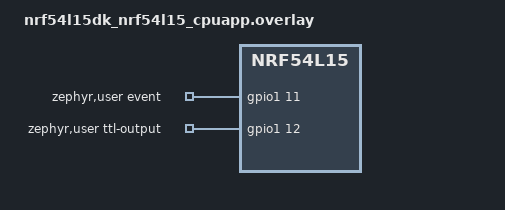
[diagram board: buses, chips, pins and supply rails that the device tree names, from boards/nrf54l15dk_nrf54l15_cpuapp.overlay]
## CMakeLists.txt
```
cmake_minimum_required(VERSION 3.20.0)
find_package(Zephyr REQUIRED HINTS $ENV{ZEPHYR_BASE})

project(galapagos)

target_include_directories(app PRIVATE
  ${CMAKE_CURRENT_SOURCE_DIR}/../shared/include
  ${CMAKE_CURRENT_SOURCE_DIR}/src
)

target_sources(app PRIVATE
  src/main.cpp
  src/debug_log.cpp
  src/record_stream.cpp
  src/hardware.cpp
  src/application.cpp
  src/ble_service.cpp
  ../shared/src/sdc_anchor_report.c
  ../shared/src/transport.cpp
  ../shared/src/fairy_protocol.cpp
  ../shared/src/adelie_protocol.cpp
  ../shared/src/magellan_protocol.cpp
)

target_compile_options(app PRIVATE
  -Wall
  -Wextra
  -Wshadow
  $<$<COMPILE_LANGUAGE:CXX>:-fno-exceptions>
  $<$<COMPILE_LANGUAGE:CXX>:-fno-rtti>
)

if(DEFINED FAIRY_ENABLE_DEBUG_STREAM)
  target_compile_definitions(app PRIVATE
    FAIRY_ENABLE_DEBUG_STREAM=${FAIRY_ENABLE_DEBUG_STREAM}
  )
endif()
```

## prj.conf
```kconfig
CONFIG_CPP=y
CONFIG_STD_CPP17=y
CONFIG_GLIBCXX_LIBCPP=y


CONFIG_SERIAL=y
CONFIG_CONSOLE=y
CONFIG_UART_CONSOLE=y
CONFIG_PRINTK=y
CONFIG_CBPRINTF_FULL_INTEGRAL=y

CONFIG_BT=y
CONFIG_BT_PERIPHERAL=y
CONFIG_BT_CENTRAL=n
CONFIG_BT_DEVICE_NAME="galapagos"
CONFIG_BT_MAX_CONN=1
CONFIG_BT_CTLR_SDC_PERIPHERAL_COUNT=1
CONFIG_BT_CTLR_SDC_CONN_ANCHOR_POINT_REPORT=y
CONFIG_BT_HCI_VS_EVT_USER=y

CONFIG_BT_L2CAP_TX_MTU=247
CONFIG_BT_BUF_ACL_RX_SIZE=251
CONFIG_BT_BUF_ACL_TX_SIZE=251
CONFIG_BT_BUF_ACL_TX_COUNT=12
CONFIG_BT_BUF_EVT_RX_COUNT=13
CONFIG_BT_CTLR_PHY_2M=y

CONFIG_MAIN_STACK_SIZE=4096
CONFIG_SYSTEM_WORKQUEUE_STACK_SIZE=4096
CONFIG_HEAP_MEM_POOL_SIZE=2048
CONFIG_ASSERT=y
CONFIG_LOG=n

CONFIG_GPIO=n
CONFIG_NRFX_GPIOTE=y
CONFIG_NRFX_GPPI=y
CONFIG_NRFX_GRTC=y

CONFIG_CLOCK_CONTROL=y
CONFIG_CLOCK_CONTROL_NRF=y
CONFIG_CLOCK_CONTROL_NRF_K32SRC_XTAL=y
```

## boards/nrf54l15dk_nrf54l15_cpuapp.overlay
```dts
#include <zephyr/dt-bindings/gpio/gpio.h>

/ {
    zephyr,user {
        event-gpios = <&gpio1 11 GPIO_ACTIVE_HIGH>;
        ttl-output-gpios = <&gpio1 12 GPIO_ACTIVE_HIGH>;
    };
};
```

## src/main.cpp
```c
#include <zephyr/kernel.h>

#include "application.hpp"
#include "ble_service.hpp"
#include "debug_log.hpp"
#include "hardware.hpp"
#include "record_stream.hpp"

int main() {
  galapagos_stream::initialize();
  int error = galapagos_hardware::initialize();
  if (error == 0) {
    galapagos_application::initialize();
    error = galapagos_ble::initialize();
  }
  if (error != 0) {
    galapagos_debug::log("FATAL galapagos status=%d\r\n", error);
  } else {
    galapagos_debug::log(
        "READY galapagos fairy=3 adelie=2 transport=1 timer_hz=16000000\r\n");
  }
  while (true) {
    k_sleep(K_SECONDS(60));
  }
  return 0;
}
```

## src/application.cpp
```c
#include "application.hpp"

#include <zephyr/kernel.h>
#include <zephyr/sys/atomic.h>

#include "fairy_shared/adelie_protocol.hpp"
#include "fairy_shared/fairy_protocol.hpp"
#include "fairy_shared/tlv.hpp"
#include "hardware.hpp"
#include "record_stream.hpp"

namespace galapagos_application {
namespace {

atomic_t active_session;
std::uint32_t last_command;
bool link_connected;
K_SEM_DEFINE(start_sem, 0, 1);

std::uint64_t extend_controller_anchor_us(std::uint64_t raw_anchor_us) {
  /*
   * The SoftDevice anchor report contains a wrapping 32-bit microsecond
   * timestamp. Extend it around the local 64-bit GRTC time before feeding the
   * clock model; otherwise every ~71.6 minutes the model jumps into the past
   * and scheduled TTL timestamps are rejected by the hardware.
   */
  constexpr std::uint64_t wrap = 1ULL << 32U;
  constexpr std::uint64_t half_wrap = wrap / 2ULL;
  const std::uint64_t near_us = galapagos_hardware::now_ticks() / 16ULL;
  std::uint64_t extended =
      (near_us & ~(wrap - 1ULL)) | (raw_anchor_us & (wrap - 1ULL));
  if (extended + half_wrap < near_us) {
    extended += wrap;
  } else if (extended > near_us + half_wrap && extended >= wrap) {
    extended -= wrap;
  }
  return extended;
}

std::uint32_t session_value() {
  return static_cast<std::uint32_t>(atomic_get(&active_session));
}

void publish_boot() {
  std::uint8_t payload[64]{};
  fairy::protocol::TlvWriter fields(payload, sizeof(payload));
  (void)fields.string(
      static_cast<std::uint16_t>(fairy::protocol::Field::board_kind),
      "nrf54l15dk");
  (void)fields.string(
      static_cast<std::uint16_t>(fairy::protocol::Field::firmware_version),
      "3.0.0");
  (void)galapagos_stream::publish_record(
      fairy::protocol::RecordType::boot, fairy::protocol::first_after_reset,
      galapagos_hardware::now_ticks(), 0, payload, fields.size());
}

bool command_u32(const fairy::protocol::AdelieMessageView &message,
                 fairy::protocol::CommandField wanted, std::uint32_t &value) {
  fairy::protocol::TlvReader reader(message.payload,
                                    message.header.payload_length);
  fairy::protocol::FieldView field;
  while (reader.next(field)) {
    if (field.tag == static_cast<std::uint16_t>(wanted)) {
      return fairy::protocol::TlvReader::as_u32(field, value);
    }
  }
  return false;
}

void publish_result(const fairy::protocol::AdelieMessageView &command,
                    fairy::protocol::Status status, std::uint64_t ticks) {
  std::uint8_t payload[64]{};
  fairy::protocol::TlvWriter fields(payload, sizeof(payload));
  (void)fields.u32(
      static_cast<std::uint16_t>(fairy::protocol::Field::command_id),
      command.header.command_id);
  (void)fields.u16(
      static_cast<std::uint16_t>(fairy::protocol::Field::operation),
      static_cast<std::uint16_t>(command.header.opcode));
  (void)fields.u8(static_cast<std::uint16_t>(fairy::protocol::Field::status),
                  static_cast<std::uint8_t>(status));
  (void)fields.u64(
      static_cast<std::uint16_t>(fairy::protocol::Field::requested_ticks),
      command.header.execute_at_ticks);
  (void)fields.u64(
      static_cast<std::uint16_t>(fairy::protocol::Field::actual_ticks), ticks);
  (void)galapagos_stream::publish_record(
      fairy::protocol::RecordType::command_result,
      fairy::protocol::critical | fairy::protocol::actual_time, ticks,
      session_value(), payload, fields.size());
}

void health_thread(void *, void *, void *) {
  k_sem_take(&start_sem, K_FOREVER);
  while (true) {
    k_sleep(K_SECONDS(1));
    const std::uint64_t ticks = galapagos_hardware::now_ticks();
    std::uint8_t payload[80]{};
    fairy::protocol::TlvWriter fields(payload, sizeof(payload));
    (void)fields.u32(
        static_cast<std::uint16_t>(fairy::protocol::Field::uptime_ms),
        static_cast<std::uint32_t>(ticks / 16'000ULL));
    (void)fields.u32(
        static_cast<std::uint16_t>(fairy::protocol::Field::dropped_records),
        galapagos_stream::dropped());
    (void)fields.u32(
        static_cast<std::uint16_t>(fairy::protocol::Field::transport_errors),
        galapagos_stream::transport_errors());
    (void)fields.boolean(
        static_cast<std::uint16_t>(fairy::protocol::Field::state),
        galapagos_hardware::ttl_armed());
    (void)galapagos_stream::publish_record(fairy::protocol::RecordType::health,
                                           0, ticks, session_value(), payload,
                                           fields.size());
  }
}

K_THREAD_DEFINE(health_thread_id, 1536, health_thread, nullptr, nullptr,
                nullptr, 9, 0, 0);

} // namespace

void initialize() {
  atomic_clear(&active_session);
  last_command = 0;
  link_connected = false;
  k_sem_give(&start_sem);
}

std::size_t handle_command(const std::uint8_t *message, std::size_t length,
                           std::uint8_t *response, std::size_t capacity) {
  fairy::protocol::AdelieMessageView command;
  if (!fairy::protocol::decode_adelie(message, length, command) ||
      command.header.kind != fairy::protocol::MessageKind::command) {
    return 0;
  }

  fairy::protocol::Status status = fairy::protocol::Status::ok;
  const std::uint64_t now = galapagos_hardware::now_ticks();
  const std::uint32_t current_session = session_value();
  if (command.header.command_id == last_command &&
      command.header.command_id != 0U) {
    status = fairy::protocol::Status::duplicate;
  } else {
    switch (command.header.opcode) {
    case fairy::protocol::Opcode::ping:
    case fairy::protocol::Opcode::get_health:
      break;

    case fairy::protocol::Opcode::start_session:
      if (command.header.session_id == 0U) {
        status = fairy::protocol::Status::invalid_parameter;
      } else if (current_session != 0U &&
                 current_session != command.header.session_id) {
        status = fairy::protocol::Status::busy;
      } else {
        atomic_set(&active_session,
                   static_cast<atomic_val_t>(command.header.session_id));
        galapagos_hardware::set_session(command.header.session_id);
      }
      break;

    case fairy::protocol::Opcode::stop_session:
      if (current_session != 0U &&
          command.header.session_id != current_session) {
        status = fairy::protocol::Status::session_mismatch;
      } else {
        atomic_clear(&active_session);
        galapagos_hardware::set_session(0);
        galapagos_hardware::force_ttl_low();
      }
      break;

    case fairy::protocol::Opcode::schedule_ttl: {
      if (current_session == 0U ||
          command.header.session_id != current_session) {
        status = fairy::protocol::Status::session_mismatch;
        break;
      }
      std::uint32_t width{};
      std::uint32_t sequence = command.header.command_id;
      if (!command_u32(command, fairy::protocol::CommandField::ttl_width_us,
                       width)) {
        status = fairy::protocol::Status::invalid_parameter;
        break;
      }
      (void)command_u32(command, fairy::protocol::CommandField::sequence,
                        sequence);
      status = galapagos_hardware::schedule_ttl(
          sequence, command.header.execute_at_ticks, width);
      break;
    }

    case fairy::protocol::Opcode::stop_ttl_train:
      galapagos_hardware::force_ttl_low();
      break;

    default:
      status = fairy::protocol::Status::unsupported;
      break;
    }
    last_command = command.header.command_id;
    publish_result(command, status, now);
  }

  fairy::protocol::MessageHeader header = command.header;
  header.kind = fairy::protocol::MessageKind::response;
  header.status = status;
  header.flags = 0;
  return fairy::protocol::encode_adelie(header, nullptr, 0, response, capacity);
}

void anchor_observation(std::uint16_t event_counter, std::uint64_t anchor_us) {
  const std::uint32_t current_session = session_value();
  std::uint8_t payload[24]{};
  fairy::protocol::TlvWriter fields(payload, sizeof(payload));
  (void)fields.u32(static_cast<std::uint16_t>(fairy::protocol::Field::sequence),
                   event_counter);
  (void)galapagos_stream::publish_record(
      fairy::protocol::RecordType::sync_observation,
      current_session == 0U ? 0U : fairy::protocol::synchronized,
      extend_controller_anchor_us(anchor_us) * 16ULL, current_session, payload,
      fields.size());
}

void connected() {
  link_connected = true;
  publish_boot();
}

void disconnected() {
  link_connected = false;
  atomic_clear(&active_session);
  galapagos_hardware::set_session(0);
  galapagos_hardware::force_ttl_low();
}

} // namespace galapagos_application
```

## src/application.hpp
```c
#pragma once

#include <cstddef>
#include <cstdint>

namespace galapagos_application {

void initialize();
std::size_t handle_command(const std::uint8_t *message, std::size_t length,
                           std::uint8_t *response, std::size_t capacity);
void anchor_observation(std::uint16_t event_counter, std::uint64_t anchor_us);
void connected();
void disconnected();

} // namespace galapagos_application
```

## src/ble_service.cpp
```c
#include "ble_service.hpp"

#include <algorithm>
#include <array>
#include <cerrno>
#include <cstring>

#include <zephyr/bluetooth/bluetooth.h>
#include <zephyr/bluetooth/conn.h>
#include <zephyr/bluetooth/gatt.h>
#include <zephyr/bluetooth/hci.h>
#include <zephyr/bluetooth/uuid.h>
#include <zephyr/kernel.h>
#include <zephyr/net_buf.h>
#include <zephyr/sys/atomic.h>

#include "application.hpp"
#include "debug_log.hpp"
#include "fairy_shared/sdc_anchor_report.h"
#include "fairy_shared/system_config.hpp"
#include "fairy_shared/transport.hpp"
#include "record_stream.hpp"

namespace galapagos_ble {
namespace {

#define BT_UUID_GALAPAGOS_SERVICE_VAL                                          \
  BT_UUID_128_ENCODE(0xA88278D0, 0x7009, 0x4BEE, 0xA6F8, 0xE1DC3FF02B92)
#define BT_UUID_GALAPAGOS_RX_VAL                                               \
  BT_UUID_128_ENCODE(0xA88278D1, 0x7009, 0x4BEE, 0xA6F8, 0xE1DC3FF02B92)
#define BT_UUID_GALAPAGOS_TX_VAL                                               \
  BT_UUID_128_ENCODE(0xA88278D2, 0x7009, 0x4BEE, 0xA6F8, 0xE1DC3FF02B92)

const bt_uuid_128 service_uuid =
    BT_UUID_INIT_128(BT_UUID_GALAPAGOS_SERVICE_VAL);
const bt_uuid_128 rx_uuid = BT_UUID_INIT_128(BT_UUID_GALAPAGOS_RX_VAL);
const bt_uuid_128 tx_uuid = BT_UUID_INIT_128(BT_UUID_GALAPAGOS_TX_VAL);

fairy::transport::Reassembler reassembler;
bt_conn *active_connection;
atomic_t notifications_enabled;
atomic_t link_connected;
atomic_t advertising_wanted;
std::uint16_t report_every_events = 100;
std::uint16_t last_report_event;
bool have_last_report;
const bt_gatt_attr *notify_attribute;

constexpr std::int32_t advertising_restart_delay_ms = 20;
constexpr std::int32_t advertising_retry_delay_ms = 200;
const bt_le_conn_param reconnect_parameters{8U, 8U, 0U, 100U};

void advertising_work_handler(k_work *work);
K_WORK_DELAYABLE_DEFINE(advertising_work, advertising_work_handler);

ssize_t receive_write(bt_conn *, const bt_gatt_attr *, const void *buffer,
                      std::uint16_t length, std::uint16_t offset,
                      std::uint8_t) {
  if (offset != 0U || buffer == nullptr) {
    return BT_GATT_ERR(BT_ATT_ERR_INVALID_OFFSET);
  }
  fairy::transport::FrameView frame;
  if (fairy::transport::decode_frame(static_cast<const std::uint8_t *>(buffer),
                                     length, frame) !=
      fairy::transport::DecodeResult::ok) {
    return BT_GATT_ERR(BT_ATT_ERR_VALUE_NOT_ALLOWED);
  }
  if (frame.header.source != fairy::config::korora_address ||
      frame.header.destination != fairy::config::galapagos_address ||
      frame.header.channel != fairy::transport::Channel::adelie) {
    return BT_GATT_ERR(BT_ATT_ERR_AUTHORIZATION);
  }

  fairy::transport::MessageView message;
  const auto result = reassembler.accept(frame, message);
  if (result == fairy::transport::DecodeResult::incomplete) {
    return length;
  }
  if (result != fairy::transport::DecodeResult::ok) {
    return BT_GATT_ERR(BT_ATT_ERR_VALUE_NOT_ALLOWED);
  }

  std::uint8_t response[fairy::transport::max_message_size]{};
  const std::size_t response_length = galapagos_application::handle_command(
      message.payload, message.payload_length, response, sizeof(response));
  if (response_length != 0U) {
    (void)galapagos_stream::publish_application(
        fairy::transport::Channel::adelie, fairy::config::korora_address,
        message.transfer_id, fairy::transport::response, response,
        response_length);
  }
  return length;
}

void subscription_changed(const bt_gatt_attr *, std::uint16_t value) {
  const bool enabled = value == BT_GATT_CCC_NOTIFY;
  atomic_set(&notifications_enabled, enabled ? 1 : 0);
  if (enabled && active_connection != nullptr) {
    galapagos_stream::set_connection(active_connection, notify_attribute);
    galapagos_application::connected();
  } else {
    galapagos_stream::clear_connection();
    galapagos_application::disconnected();
  }
}

BT_GATT_SERVICE_DEFINE(
    galapagos_service, BT_GATT_PRIMARY_SERVICE(&service_uuid),
    BT_GATT_CHARACTERISTIC(&rx_uuid.uuid,
                           BT_GATT_CHRC_WRITE | BT_GATT_CHRC_WRITE_WITHOUT_RESP,
                           BT_GATT_PERM_WRITE, nullptr, receive_write, nullptr),
    BT_GATT_CHARACTERISTIC(&tx_uuid.uuid, BT_GATT_CHRC_NOTIFY,
                           BT_GATT_PERM_NONE, nullptr, nullptr, nullptr),
    BT_GATT_CCC(subscription_changed, BT_GATT_PERM_READ | BT_GATT_PERM_WRITE));

int start_advertising() {
  const bt_data advertising[] = {
      BT_DATA_BYTES(BT_DATA_FLAGS, BT_LE_AD_GENERAL | BT_LE_AD_NO_BREDR),
      BT_DATA(BT_DATA_NAME_COMPLETE, CONFIG_BT_DEVICE_NAME,
              sizeof(CONFIG_BT_DEVICE_NAME) - 1),
  };
  const bt_data scan_response[] = {
      BT_DATA_BYTES(BT_DATA_UUID128_ALL, BT_UUID_GALAPAGOS_SERVICE_VAL),
  };
  return bt_le_adv_start(BT_LE_ADV_CONN_FAST_1, advertising,
                         ARRAY_SIZE(advertising), scan_response,
                         ARRAY_SIZE(scan_response));
}

void request_advertising(k_timeout_t delay) {
  atomic_set(&advertising_wanted, 1);
  (void)k_work_reschedule(&advertising_work, delay);
}

void advertising_work_handler(k_work *) {
  if (atomic_get(&advertising_wanted) == 0 ||
      atomic_get(&link_connected) != 0) {
    return;
  }

  const int error = start_advertising();
  if (error == 0 || error == -EALREADY) {
    atomic_clear(&advertising_wanted);
    galapagos_debug::log("BLE_ADV status=started\r\n");
    return;
  }

  galapagos_debug::log("BLE_ADV status=retry error=%d delay_ms=%d\r\n", error,
                       advertising_retry_delay_ms);
  (void)k_work_reschedule(&advertising_work,
                          K_MSEC(advertising_retry_delay_ms));
}

void connected(bt_conn *connection, std::uint8_t error) {
  if (error != 0U) {
    atomic_clear(&link_connected);
    galapagos_debug::log("BLE_CONNECT status=failed error=%u\r\n", error);
    request_advertising(K_MSEC(advertising_restart_delay_ms));
    return;
  }

  atomic_set(&link_connected, 1);
  atomic_clear(&advertising_wanted);
  (void)k_work_cancel_delayable(&advertising_work);

  if (active_connection != nullptr) {
    bt_conn_unref(active_connection);
  }
  active_connection = bt_conn_ref(connection);
  reassembler.reset();
  have_last_report = false;
  const int parameter_error =
      bt_conn_le_param_update(connection, &reconnect_parameters);
  if (parameter_error != 0 && parameter_error != -EALREADY) {
    galapagos_debug::log("BLE_CONNECT parameter_update_error=%d\r\n",
                         parameter_error);
  }
  galapagos_debug::log("BLE_CONNECT status=connected\r\n");
}

void disconnected(bt_conn *, std::uint8_t reason) {
  atomic_clear(&link_connected);
  atomic_clear(&notifications_enabled);
  galapagos_stream::clear_connection();
  reassembler.reset();
  if (active_connection != nullptr) {
    bt_conn_unref(active_connection);
    active_connection = nullptr;
  }
  galapagos_application::disconnected();
  galapagos_debug::log(
      "BLE_CONNECT status=disconnected reason=0x%02x restart_ms=%d\r\n", reason,
      advertising_restart_delay_ms);
  request_advertising(K_MSEC(advertising_restart_delay_ms));
}

void parameters_updated(bt_conn *, std::uint16_t interval, std::uint16_t,
                        std::uint16_t) {
  const std::uint32_t interval_us = interval * 1250U;
  report_every_events = static_cast<std::uint16_t>(std::max<std::uint32_t>(
      1U, (1'000'000U + interval_us / 2U) / interval_us));
}

bt_conn_cb callbacks{};

bool anchor_event(net_buf_simple *buffer) {
  if (buffer->len < 1U) {
    return false;
  }
  const std::uint8_t subevent = net_buf_simple_pull_u8(buffer);
  if (!fairy_sdc_is_anchor_report(subevent)) {
    return false;
  }
  fairy_sdc_anchor_report_t event{};
  if (!fairy_sdc_decode_anchor_report(buffer->data, buffer->len, &event)) {
    return true;
  }
  if (atomic_get(&notifications_enabled) == 0) {
    return true;
  }
  if (!have_last_report ||
      static_cast<std::uint16_t>(event.event_counter - last_report_event) >=
          report_every_events) {
    galapagos_application::anchor_observation(event.event_counter,
                                              event.anchor_point_us);
    last_report_event = event.event_counter;
    have_last_report = true;
  }
  return true;
}

} // namespace

int initialize() {
  notify_attribute = &galapagos_service.attrs[4];
  atomic_clear(&notifications_enabled);
  atomic_clear(&link_connected);
  atomic_clear(&advertising_wanted);
  active_connection = nullptr;
  reassembler.reset();

  int error = bt_enable(nullptr);
  if (error != 0) {
    return error;
  }
  callbacks.connected = connected;
  callbacks.disconnected = disconnected;
  callbacks.le_param_updated = parameters_updated;
  bt_conn_cb_register(&callbacks);
  error = bt_hci_register_vnd_evt_cb(anchor_event);
  if (error != 0) {
    return error;
  }
  error = fairy_sdc_enable_anchor_reports();
  if (error != 0) {
    return error;
  }

  request_advertising(K_NO_WAIT);
  return 0;
}

} // namespace galapagos_ble
```

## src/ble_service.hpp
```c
#pragma once

namespace galapagos_ble {

int initialize();

} // namespace galapagos_ble
```

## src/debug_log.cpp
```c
#include "debug_log.hpp"

#include <cstdarg>
#include <cstdio>

#include <zephyr/kernel.h>
#include <zephyr/sys/printk.h>

#include "fairy_shared/system_config.hpp"

namespace galapagos_debug {
namespace {

struct Line {
  char text[192];
};

K_MSGQ_DEFINE(lines, sizeof(Line), 16, 4);

void thread(void *, void *, void *) {
  Line line;
  while (true) {
    k_msgq_get(&lines, &line, K_FOREVER);
#if FAIRY_ENABLE_DEBUG_STREAM
    printk("%s", line.text);
#endif
  }
}

K_THREAD_DEFINE(debug_thread_id, 1536, thread, nullptr, nullptr, nullptr, 8, 0,
                0);

} // namespace

void log(const char *format, ...) {
#if FAIRY_ENABLE_DEBUG_STREAM
  Line line{};
  va_list arguments;
  va_start(arguments, format);
  const int length = vsnprintk(line.text, sizeof(line.text), format, arguments);
  va_end(arguments);
  if (length > 0 && length < static_cast<int>(sizeof(line.text))) {
    (void)k_msgq_put(&lines, &line, K_NO_WAIT);
  }
#else
  (void)format;
#endif
}

} // namespace galapagos_debug
```

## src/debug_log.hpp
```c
#pragma once

namespace galapagos_debug {

void log(const char *format, ...);

} // namespace galapagos_debug
```

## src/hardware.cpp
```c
#include "hardware.hpp"

#include <cerrno>

#include <gpiote_nrfx.h>
#include <hal/nrf_gpio.h>
#include <helpers/nrfx_gppi.h>
#include <nrfx_gpiote.h>
#include <nrfx_grtc.h>

#include <zephyr/devicetree.h>
#include <zephyr/irq.h>
#include <zephyr/kernel.h>
#include <zephyr/sys/atomic.h>
#include <zephyr/sys/util.h>

#include "debug_log.hpp"
#include "fairy_shared/fairy_protocol.hpp"
#include "fairy_shared/static_queue.hpp"
#include "fairy_shared/tlv.hpp"
#include "record_stream.hpp"

namespace galapagos_hardware {
namespace {

#define USER_NODE DT_PATH(zephyr_user)
#define EVENT_INPUT_PIN NRF_DT_GPIOS_TO_PSEL(USER_NODE, event_gpios)
#define EVENT_GPIOTE_NODE NRF_DT_GPIOTE_NODE(USER_NODE, event_gpios)
#define TTL_OUTPUT_PIN NRF_DT_GPIOS_TO_PSEL(USER_NODE, ttl_output_gpios)
#define TTL_GPIOTE_NODE NRF_DT_GPIOTE_NODE(USER_NODE, ttl_output_gpios)

BUILD_ASSERT(DT_SAME_NODE(EVENT_GPIOTE_NODE, TTL_GPIOTE_NODE),
             "event and TTL pins must use the same GPIOTE instance");

nrfx_gpiote_t *const gpiote = &GPIOTE_NRFX_INST_BY_NODE(EVENT_GPIOTE_NODE);
std::uint8_t event_gpiote_channel;
std::uint8_t event_grtc_channel;
nrfx_gppi_handle_t event_connection;
std::uint8_t ttl_gpiote_channel;
std::uint8_t ttl_set_channel;
std::uint8_t ttl_clear_channel;
nrfx_gppi_handle_t ttl_set_connection;
nrfx_gppi_handle_t ttl_clear_connection;
atomic_t pulse_armed;
atomic_t active_session;
atomic_t event_sequence;

struct Pulse {
  std::uint32_t sequence{};
  std::uint64_t target_us{};
  std::uint32_t width_us{};
};

Pulse pulse;
fairy::StaticQueue<Pulse, 8> pending_pulses;
k_spinlock pulse_lock;
std::uint64_t last_queued_target_us;

void program_pulse(const Pulse &next) {
  pulse = next;
  nrfx_gppi_conn_enable(ttl_set_connection);
  nrfx_gppi_conn_enable(ttl_clear_connection);
  /*
   * The optimized GRTC setters require interrupts to be locked. Enabling the
   * channels and using safe setting also prevents a prior compare state from
   * being interpreted as the newly queued pulse.
   */
  const unsigned int key = irq_lock();
  (void)nrfx_grtc_syscounter_cc_int_enable(ttl_set_channel);
  (void)nrfx_grtc_syscounter_cc_int_enable(ttl_clear_channel);
  nrfx_grtc_syscounter_cc_abs_set(ttl_set_channel, pulse.target_us, true);
  nrfx_grtc_syscounter_cc_abs_set(ttl_clear_channel,
                                  pulse.target_us + pulse.width_us, true);
  irq_unlock(key);
}

int wait_for_grtc() {
  nrfx_grtc_active_request_set(true);
  for (std::uint32_t attempt = 0; attempt < 10'000; ++attempt) {
    if (nrfx_grtc_ready_check()) {
      return 0;
    }
    k_busy_wait(10);
  }
  return -ETIMEDOUT;
}

void gpiote_irq_wrapper(const void *argument) {
  nrfx_gpiote_irq_handler(
      static_cast<nrfx_gpiote_t *>(const_cast<void *>(argument)));
}

void event_handler(nrfx_gpiote_pin_t, nrfx_gpiote_trigger_t, void *) {
  std::uint64_t captured_us{};
  if (nrfx_grtc_syscounter_cc_value_read(event_grtc_channel, &captured_us) !=
      0) {
    return;
  }
  const std::uint32_t sequence =
      static_cast<std::uint32_t>(atomic_inc(&event_sequence) + 1);
  std::uint8_t payload[24]{};
  fairy::protocol::TlvWriter fields(payload, sizeof(payload));
  (void)fields.u32(static_cast<std::uint16_t>(fairy::protocol::Field::sequence),
                   sequence);
  (void)fields.u8(static_cast<std::uint16_t>(fairy::protocol::Field::state), 1);
  (void)galapagos_stream::publish_record(
      fairy::protocol::RecordType::digital_input,
      fairy::protocol::critical | fairy::protocol::actual_time,
      captured_us * 16ULL,
      static_cast<std::uint32_t>(atomic_get(&active_session)), payload,
      fields.size());
}

void ttl_set_handler(std::int32_t id, std::uint64_t cc_value, void *) {
  if (id != static_cast<std::int32_t>(ttl_set_channel)) {
    return;
  }
  std::uint8_t payload[40]{};
  fairy::protocol::TlvWriter fields(payload, sizeof(payload));
  (void)fields.u32(static_cast<std::uint16_t>(fairy::protocol::Field::sequence),
                   pulse.sequence);
  (void)fields.u64(
      static_cast<std::uint16_t>(fairy::protocol::Field::requested_ticks),
      pulse.target_us * 16ULL);
  (void)fields.u64(
      static_cast<std::uint16_t>(fairy::protocol::Field::actual_ticks),
      cc_value * 16ULL);
  (void)fields.u32(
      static_cast<std::uint16_t>(fairy::protocol::Field::duration_us),
      pulse.width_us);
  (void)galapagos_stream::publish_record(
      fairy::protocol::RecordType::ttl_generated,
      fairy::protocol::critical | fairy::protocol::actual_time |
          fairy::protocol::scheduled,
      cc_value * 16ULL, static_cast<std::uint32_t>(atomic_get(&active_session)),
      payload, fields.size());
}

void ttl_clear_handler(std::int32_t id, std::uint64_t, void *) {
  if (id != static_cast<std::int32_t>(ttl_clear_channel)) {
    return;
  }
  Pulse next;
  const k_spinlock_key_t key = k_spin_lock(&pulse_lock);
  const bool have_next = pending_pulses.pop(next);
  if (!have_next) {
    atomic_clear(&pulse_armed);
    last_queued_target_us = 0;
  } else {
    program_pulse(next);
  }
  k_spin_unlock(&pulse_lock, key);
}

int configure_event() {
  int error = nrfx_grtc_channel_alloc(&event_grtc_channel);
  if (error != 0) {
    return error;
  }
  error = nrfx_grtc_syscounter_capture(event_grtc_channel);
  if (error != 0) {
    return error;
  }

  IRQ_CONNECT(DT_IRQN(EVENT_GPIOTE_NODE), DT_IRQ(EVENT_GPIOTE_NODE, priority),
              gpiote_irq_wrapper, gpiote, 0);
  if (!nrfx_gpiote_init_check(gpiote)) {
    error = nrfx_gpiote_init(gpiote, DT_IRQ(EVENT_GPIOTE_NODE, priority));
    if (error != 0) {
      return error;
    }
  }
  irq_enable(DT_IRQN(EVENT_GPIOTE_NODE));
  error = nrfx_gpiote_channel_alloc(gpiote, &event_gpiote_channel);
  if (error != 0) {
    return error;
  }

  static const nrf_gpio_pin_pull_t pull = NRF_GPIO_PIN_PULLDOWN;
  nrfx_gpiote_trigger_config_t trigger{};
  trigger.trigger = NRFX_GPIOTE_TRIGGER_LOTOHI;
  trigger.p_in_channel = &event_gpiote_channel;
  nrfx_gpiote_handler_config_t handler{};
  handler.handler = event_handler;
  handler.p_context = nullptr;
  nrfx_gpiote_input_pin_config_t input{};
  input.p_pull_config = &pull;
  input.p_trigger_config = &trigger;
  input.p_handler_config = &handler;
  error = nrfx_gpiote_input_configure(gpiote, EVENT_INPUT_PIN, &input);
  if (error != 0) {
    return error;
  }
  error = nrfx_gppi_conn_alloc(
      nrfx_gpiote_in_event_address_get(gpiote, EVENT_INPUT_PIN),
      nrfx_grtc_capture_task_address_get(event_grtc_channel),
      &event_connection);
  if (error != 0) {
    return error;
  }
  nrfx_gppi_conn_enable(event_connection);
  nrfx_gpiote_trigger_enable(gpiote, EVENT_INPUT_PIN, true);
  return 0;
}

int configure_ttl() {
#if !defined(GPIOTE_FEATURE_SET_PRESENT) || !defined(GPIOTE_FEATURE_CLR_PRESENT)
#error "Galapagos TTL requires GPIOTE SET and CLR tasks"
#endif
  int error = nrfx_gpiote_channel_alloc(gpiote, &ttl_gpiote_channel);
  if (error != 0) {
    return error;
  }
  static nrfx_gpiote_output_config_t output{};
  output.drive = NRF_GPIO_PIN_S0S1;
  output.input_connect = NRF_GPIO_PIN_INPUT_CONNECT;
  output.pull = NRF_GPIO_PIN_NOPULL;
  nrfx_gpiote_task_config_t task{};
  task.task_ch = ttl_gpiote_channel;
  task.polarity = NRF_GPIOTE_POLARITY_TOGGLE;
  task.init_val = NRF_GPIOTE_INITIAL_VALUE_LOW;
  error = nrfx_gpiote_output_configure(gpiote, TTL_OUTPUT_PIN, &output, &task);
  if (error != 0) {
    return error;
  }
  nrfx_gpiote_out_task_enable(gpiote, TTL_OUTPUT_PIN);
  nrfx_gpiote_clr_task_trigger(gpiote, TTL_OUTPUT_PIN);

  if ((error = nrfx_grtc_channel_alloc(&ttl_set_channel)) != 0 ||
      (error = nrfx_grtc_channel_alloc(&ttl_clear_channel)) != 0) {
    return error;
  }
  nrfx_grtc_channel_callback_set(ttl_set_channel, ttl_set_handler, nullptr);
  nrfx_grtc_channel_callback_set(ttl_clear_channel, ttl_clear_handler, nullptr);
  error = nrfx_gppi_conn_alloc(
      nrfx_grtc_event_compare_address_get(ttl_set_channel),
      nrfx_gpiote_set_task_address_get(gpiote, TTL_OUTPUT_PIN),
      &ttl_set_connection);
  if (error != 0) {
    return error;
  }
  error = nrfx_gppi_conn_alloc(
      nrfx_grtc_event_compare_address_get(ttl_clear_channel),
      nrfx_gpiote_clr_task_address_get(gpiote, TTL_OUTPUT_PIN),
      &ttl_clear_connection);
  if (error != 0) {
    return error;
  }
  nrfx_gppi_conn_enable(ttl_set_connection);
  nrfx_gppi_conn_enable(ttl_clear_connection);
  return 0;
}

} // namespace

int initialize() {
  atomic_clear(&pulse_armed);
  atomic_clear(&active_session);
  atomic_clear(&event_sequence);
  pending_pulses.clear();
  last_queued_target_us = 0;
  int error = wait_for_grtc();
  if (error == 0) {
    error = configure_event();
  }
  if (error == 0) {
    error = configure_ttl();
  }
  galapagos_debug::log(
      "HARDWARE galapagos event_pin=%u ttl_pin=%u status=%d\r\n",
      static_cast<unsigned int>(EVENT_INPUT_PIN),
      static_cast<unsigned int>(TTL_OUTPUT_PIN), error);
  return error;
}

std::uint64_t now_ticks() { return nrfx_grtc_syscounter_get() * 16ULL; }

void set_session(std::uint32_t session_id) {
  atomic_set(&active_session, static_cast<atomic_val_t>(session_id));
}

fairy::protocol::Status schedule_ttl(std::uint32_t sequence,
                                     std::uint64_t target_ticks,
                                     std::uint32_t width_us) {
  if (target_ticks % 16ULL != 0ULL || width_us == 0U || width_us > 2'000'000U) {
    return fairy::protocol::Status::invalid_parameter;
  }
  const std::uint64_t target_us = target_ticks / 16ULL;
  const std::uint64_t now_us = nrfx_grtc_syscounter_get();

  const std::int64_t lead_us =
      target_us >= now_us ? static_cast<std::int64_t>(target_us - now_us)
                          : -static_cast<std::int64_t>(now_us - target_us);

  if (target_us <= now_us || target_us - now_us < 50'000ULL ||
      UINT64_MAX - target_us < width_us) {
    galapagos_debug::log("TTL_REJECT sequence=%u target_us=%llu now_us=%llu "
                         "lead_us=%lld width_us=%u modulo=%u\r\n",
                         sequence, static_cast<unsigned long long>(target_us),
                         static_cast<unsigned long long>(now_us),
                         static_cast<long long>(lead_us), width_us,
                         static_cast<unsigned int>(target_ticks % 16ULL));

    return fairy::protocol::Status::invalid_parameter;
  }
  const k_spinlock_key_t key = k_spin_lock(&pulse_lock);
  if (atomic_get(&pulse_armed) != 0) {
    if (target_us <= last_queued_target_us ||
        !pending_pulses.push(Pulse{sequence, target_us, width_us})) {
      k_spin_unlock(&pulse_lock, key);
      return fairy::protocol::Status::queue_full;
    }
    last_queued_target_us = target_us;
    k_spin_unlock(&pulse_lock, key);
    return fairy::protocol::Status::accepted;
  }
  atomic_set(&pulse_armed, 1);
  const Pulse first{sequence, target_us, width_us};
  last_queued_target_us = target_us;
  program_pulse(first);
  k_spin_unlock(&pulse_lock, key);
  return fairy::protocol::Status::accepted;
}

void force_ttl_low() {
  const k_spinlock_key_t key = k_spin_lock(&pulse_lock);
  nrfx_gppi_conn_disable(ttl_set_connection);
  nrfx_gppi_conn_disable(ttl_clear_connection);
  (void)nrfx_grtc_syscounter_cc_int_disable(ttl_set_channel);
  (void)nrfx_grtc_syscounter_cc_int_disable(ttl_clear_channel);
  (void)nrfx_grtc_syscounter_cc_disable(ttl_set_channel);
  (void)nrfx_grtc_syscounter_cc_disable(ttl_clear_channel);
  pending_pulses.clear();
  last_queued_target_us = 0;
  atomic_clear(&pulse_armed);
  nrfx_gpiote_clr_task_trigger(gpiote, TTL_OUTPUT_PIN);
  k_spin_unlock(&pulse_lock, key);
}

bool ttl_armed() { return atomic_get(&pulse_armed) != 0; }

} // namespace galapagos_hardware
```

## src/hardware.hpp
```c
#pragma once

#include <cstdint>

#include "fairy_shared/adelie_protocol.hpp"

namespace galapagos_hardware {

int initialize();
std::uint64_t now_ticks();
void set_session(std::uint32_t session_id);

fairy::protocol::Status schedule_ttl(std::uint32_t sequence,
                                     std::uint64_t target_ticks,
                                     std::uint32_t width_us);
void force_ttl_low();
bool ttl_armed();

} // namespace galapagos_hardware
```

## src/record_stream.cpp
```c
#include "record_stream.hpp"

#include <algorithm>
#include <array>
#include <cerrno>
#include <cstring>

#include <zephyr/bluetooth/conn.h>
#include <zephyr/bluetooth/gatt.h>
#include <zephyr/kernel.h>
#include <zephyr/sys/atomic.h>

#include "debug_log.hpp"
#include "fairy_shared/system_config.hpp"

namespace galapagos_stream {
namespace {

struct Outbound {
  fairy::transport::Channel channel{};
  std::uint8_t destination{};
  std::uint8_t flags{};
  std::uint16_t transfer_id{};
  std::uint16_t length{};
  std::array<std::uint8_t, fairy::transport::max_message_size> payload{};
};

K_MSGQ_DEFINE(control_outbound_queue, sizeof(Outbound), 8, 4);
K_MSGQ_DEFINE(record_outbound_queue, sizeof(Outbound), 48, 4);
K_SEM_DEFINE(outbound_ready, 0, 1);
K_MUTEX_DEFINE(connection_mutex);

struct NotificationSlot {
  atomic_t in_use{};
  bt_gatt_notify_params params{};
  std::array<std::uint8_t, fairy::transport::max_raw_frame_size> frame{};
};

std::array<NotificationSlot, 2> notification_slots{};
K_SEM_DEFINE(notification_slot_available, 2, 2);

bt_conn *active_connection;
const bt_gatt_attr *active_attribute;
atomic_t dropped_count;
atomic_t error_count;
atomic_t record_id;
atomic_t next_transfer = ATOMIC_INIT(1);

void release_notification_slot(NotificationSlot *slot) {
  if (slot == nullptr) {
    return;
  }
  atomic_clear(&slot->in_use);
  k_sem_give(&notification_slot_available);
}

void notify_complete(bt_conn *, void *user_data) {
  release_notification_slot(static_cast<NotificationSlot *>(user_data));
}

void reset_notification_slots() {
  k_sem_reset(&notification_slot_available);
  for (NotificationSlot &slot : notification_slots) {
    atomic_clear(&slot.in_use);
  }
  for (std::size_t index = 0; index < notification_slots.size(); ++index) {
    k_sem_give(&notification_slot_available);
  }
}

NotificationSlot *acquire_notification_slot() {
  if (k_sem_take(&notification_slot_available, K_MSEC(75)) != 0) {
    return nullptr;
  }
  for (NotificationSlot &slot : notification_slots) {
    if (atomic_cas(&slot.in_use, 0, 1)) {
      return &slot;
    }
  }
  k_sem_give(&notification_slot_available);
  return nullptr;
}

bool queue_notification(bt_conn *connection, const bt_gatt_attr *attribute,
                        const std::uint8_t *frame, std::size_t length) {
  if (length > fairy::transport::max_raw_frame_size) {
    return false;
  }
  NotificationSlot *slot = acquire_notification_slot();
  if (slot == nullptr) {
    return false;
  }
  std::memcpy(slot->frame.data(), frame, length);
  slot->params = {};
  slot->params.attr = attribute;
  slot->params.data = slot->frame.data();
  slot->params.len = static_cast<std::uint16_t>(length);
  slot->params.func = notify_complete;
  slot->params.user_data = slot;

  int error = -EAGAIN;
  for (unsigned int attempt = 0; attempt < 50U; ++attempt) {
    error = bt_gatt_notify_cb(connection, &slot->params);
    if (error == -ENOMEM || error == -EAGAIN) {
      k_sleep(K_MSEC(2));
      continue;
    }
    break;
  }
  if (error != 0) {
    release_notification_slot(slot);
  }
  return error == 0;
}

void notification_thread(void *, void *, void *) {
  Outbound outbound;
  std::array<std::uint8_t, fairy::transport::max_raw_frame_size> frame{};

  while (true) {
    if (k_msgq_get(&control_outbound_queue, &outbound, K_NO_WAIT) != 0 &&
        k_msgq_get(&record_outbound_queue, &outbound, K_NO_WAIT) != 0) {
      k_sem_take(&outbound_ready, K_FOREVER);
      continue;
    }

    k_mutex_lock(&connection_mutex, K_FOREVER);
    bt_conn *connection =
        active_connection == nullptr ? nullptr : bt_conn_ref(active_connection);
    const bt_gatt_attr *attribute = active_attribute;
    k_mutex_unlock(&connection_mutex);
    if (connection == nullptr || attribute == nullptr) {
      atomic_inc(&dropped_count);
      continue;
    }

    const std::uint16_t mtu = bt_gatt_get_mtu(connection);
    const std::size_t fragment_capacity = std::max<std::size_t>(
        1U, std::min<std::size_t>(fairy::transport::max_fragment_payload,
                                  mtu > 17U ? mtu - 17U : 1U));
    const std::size_t fragment_count =
        outbound.length == 0U
            ? 1U
            : (outbound.length + fragment_capacity - 1U) / fragment_capacity;

    bool failed = fragment_count > 255U;
    for (std::size_t index = 0; !failed && index < fragment_count; ++index) {
      const std::size_t offset = index * fragment_capacity;
      const std::size_t chunk =
          outbound.length == 0U
              ? 0U
              : std::min(fragment_capacity,
                         static_cast<std::size_t>(outbound.length) - offset);
      fairy::transport::Header header;
      header.channel = outbound.channel;
      header.flags = outbound.flags;
      if (index == 0U) {
        header.flags |= fairy::transport::first_fragment;
      }
      if (index + 1U == fragment_count) {
        header.flags |= fairy::transport::last_fragment;
      }
      header.source = fairy::config::galapagos_address;
      header.destination = outbound.destination;
      header.fragment_index = static_cast<std::uint8_t>(index);
      header.fragment_count = static_cast<std::uint8_t>(fragment_count);
      header.transfer_id = outbound.transfer_id;

      const std::size_t frame_length = fairy::transport::encode_frame(
          header, chunk == 0U ? nullptr : outbound.payload.data() + offset,
          chunk, frame.data(), frame.size());
      if (frame_length == 0U) {
        failed = true;
        break;
      }

      if (!queue_notification(connection, attribute, frame.data(),
                              frame_length)) {
        failed = true;
      }
    }

    if (failed) {
      atomic_inc(&error_count);
    }
    bt_conn_unref(connection);
  }
}

K_THREAD_DEFINE(notification_thread_id, 3072, notification_thread, nullptr,
                nullptr, nullptr, 6, 0, 0);

} // namespace

void initialize() {
  atomic_set(&dropped_count, 0);
  atomic_set(&error_count, 0);
  atomic_set(&record_id, 0);
}

void set_connection(bt_conn *connection, const bt_gatt_attr *notify_attribute) {
  k_mutex_lock(&connection_mutex, K_FOREVER);
  if (active_connection != nullptr) {
    bt_conn_unref(active_connection);
  }
  active_connection = connection == nullptr ? nullptr : bt_conn_ref(connection);
  active_attribute = notify_attribute;
  k_mutex_unlock(&connection_mutex);
}

void clear_connection() {
  k_mutex_lock(&connection_mutex, K_FOREVER);
  if (active_connection != nullptr) {
    bt_conn_unref(active_connection);
    active_connection = nullptr;
  }
  active_attribute = nullptr;
  k_mutex_unlock(&connection_mutex);
  k_msgq_purge(&control_outbound_queue);
  k_msgq_purge(&record_outbound_queue);
  k_sem_reset(&outbound_ready);
  reset_notification_slots();
}

bool publish_record(fairy::protocol::RecordType type, std::uint16_t flags,
                    std::uint64_t ticks, std::uint32_t session_id,
                    const std::uint8_t *payload, std::size_t payload_length) {
  Outbound message;
  message.channel = fairy::transport::Channel::fairy;
  message.destination = fairy::config::korora_address;
  message.transfer_id =
      static_cast<std::uint16_t>(atomic_inc(&next_transfer) + 1);
  fairy::protocol::RecordHeader header;
  header.type = type;
  header.flags = flags;
  header.record_id = static_cast<std::uint32_t>(atomic_inc(&record_id) + 1);
  header.session_id = session_id;
  header.timestamp_ticks = ticks;
  header.clock_hz = fairy::config::common_timer_hz;
  const std::size_t length = fairy::protocol::encode_record(
      header, payload, payload_length, message.payload.data(),
      message.payload.size());
  if (length == 0U) {
    atomic_inc(&dropped_count);
    return false;
  }
  message.length = static_cast<std::uint16_t>(length);
  if (k_msgq_put(&record_outbound_queue, &message, K_NO_WAIT) != 0) {
    atomic_inc(&dropped_count);
    return false;
  }
  k_sem_give(&outbound_ready);
  return true;
}

bool publish_application(fairy::transport::Channel channel,
                         std::uint8_t destination, std::uint16_t transfer_id,
                         std::uint8_t flags, const std::uint8_t *payload,
                         std::size_t payload_length) {
  if (payload_length > fairy::transport::max_message_size ||
      (payload_length != 0U && payload == nullptr)) {
    return false;
  }
  Outbound message;
  message.channel = channel;
  message.destination = destination;
  message.transfer_id = transfer_id;
  message.flags = flags;
  message.length = static_cast<std::uint16_t>(payload_length);
  if (payload_length != 0U) {
    std::memcpy(message.payload.data(), payload, payload_length);
  }
  if (k_msgq_put(&control_outbound_queue, &message, K_NO_WAIT) != 0) {
    atomic_inc(&dropped_count);
    return false;
  }
  k_sem_give(&outbound_ready);
  return true;
}

std::uint32_t dropped() {
  return static_cast<std::uint32_t>(atomic_get(&dropped_count));
}

std::uint32_t transport_errors() {
  return static_cast<std::uint32_t>(atomic_get(&error_count));
}

} // namespace galapagos_stream
```

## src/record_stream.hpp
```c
#pragma once

#include <cstddef>
#include <cstdint>

#include "fairy_shared/fairy_protocol.hpp"
#include "fairy_shared/transport.hpp"

struct bt_conn;
struct bt_gatt_attr;

namespace galapagos_stream {

void initialize();
void set_connection(bt_conn *connection, const bt_gatt_attr *notify_attribute);
void clear_connection();

bool publish_record(fairy::protocol::RecordType type, std::uint16_t flags,
                    std::uint64_t ticks, std::uint32_t session_id,
                    const std::uint8_t *payload = nullptr,
                    std::size_t payload_length = 0);

bool publish_application(fairy::transport::Channel channel,
                         std::uint8_t destination, std::uint16_t transfer_id,
                         std::uint8_t flags, const std::uint8_t *payload,
                         std::size_t payload_length);

std::uint32_t dropped();
std::uint32_t transport_errors();

} // namespace galapagos_stream
```
